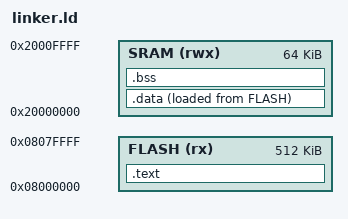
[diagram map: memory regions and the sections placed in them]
ENTRY(Reset_Handler)

MEMORY
{
	FLASH (rx) : ORIGIN = 0x08000000, LENGTH = 512K
    SRAM (rwx) : ORIGIN = 0x20000000, LENGTH = 64K
}

SECTIONS
{
	.text :
	{
		_stext = .;
		KEEP(*(.isr_vector))
		*(.text*)
		*(.rodata*)
		_etext = .;
	}> FLASH 
	
	.data :
	{
		_sdata = .;
		*(.data)
		_edata = .;
		_la_data = LOADADDR(.data);
	}> SRAM AT> FLASH

	
	.bss :
	{
		_sbss = .;
		*(.bss*)
		*(COMMON)
		_ebss = .;
	}> SRAM
}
